# STM32MP23_CM33 register map
File version: 1.2
CPU: CM33 r0p1, little endian, MPU, FPU, vendor SysTick, 8 interrupt priority bits
Registers are 32-bit, read-write, reset 0x0 unless marked. A register's access mark holds for its fields unless they carry their own. Offsets are from the block's base; [hi:lo] are bit positions; {n}, {i} and the like mark numbered series; 'fields as' and 'values as' point back to an identical list.

## BSEC — BSEC register block
Base 0x44000000
Same registers: BSEC_S 0x54000000
{0x0+4i} BSEC_FVR{i} reset not defined (i=0..375) — BSEC fuse word {i} value register
  [31:0] FV — fuse value
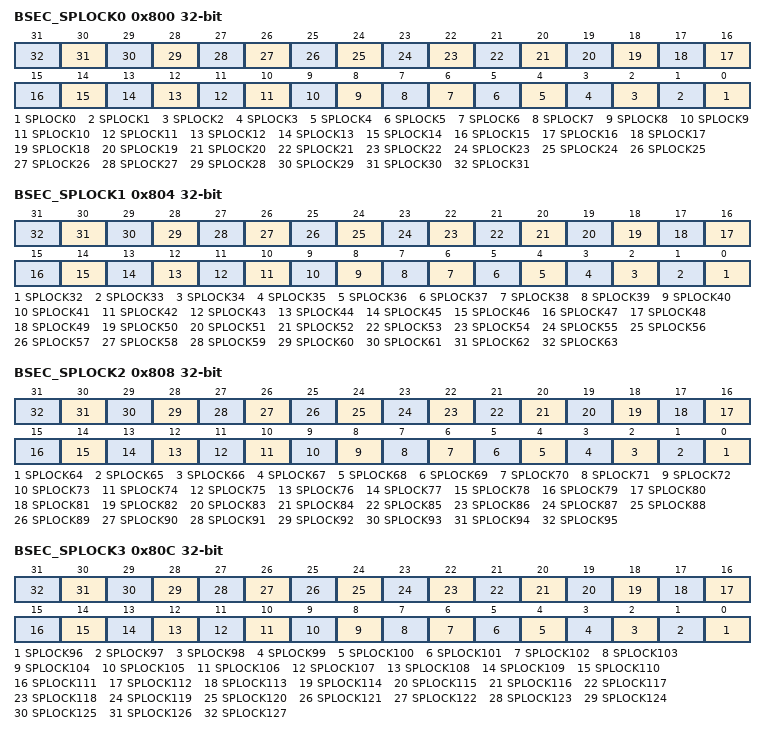
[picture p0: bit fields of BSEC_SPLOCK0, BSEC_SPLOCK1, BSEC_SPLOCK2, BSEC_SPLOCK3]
0x800 BSEC_SPLOCK0 — BSEC sticky programming lock register 0
  [n] SPLOCK{n} (n=0..31) — Sticky programming lock for word {n}
    0=Fuse word {n} can be burnt in fuse memory array; 1=Attempt to program fuse word {n} in OTP memory array is silently ignored
0x804 BSEC_SPLOCK1 — BSEC sticky programming lock register 1
  [n-32] SPLOCK{n} (n=32..63) — Sticky programming lock for word {n}
    values as BSEC_SPLOCK0.SPLOCK0
0x808 BSEC_SPLOCK2 — BSEC sticky programming lock register 2
  [n-64] SPLOCK{n} (n=64..95) — Sticky programming lock for word {n}
    values as BSEC_SPLOCK0.SPLOCK0
0x80C BSEC_SPLOCK3 — BSEC sticky programming lock register 3
  [n-96] SPLOCK{n} (n=96..127) — Sticky programming lock for word {n}
    values as BSEC_SPLOCK0.SPLOCK0
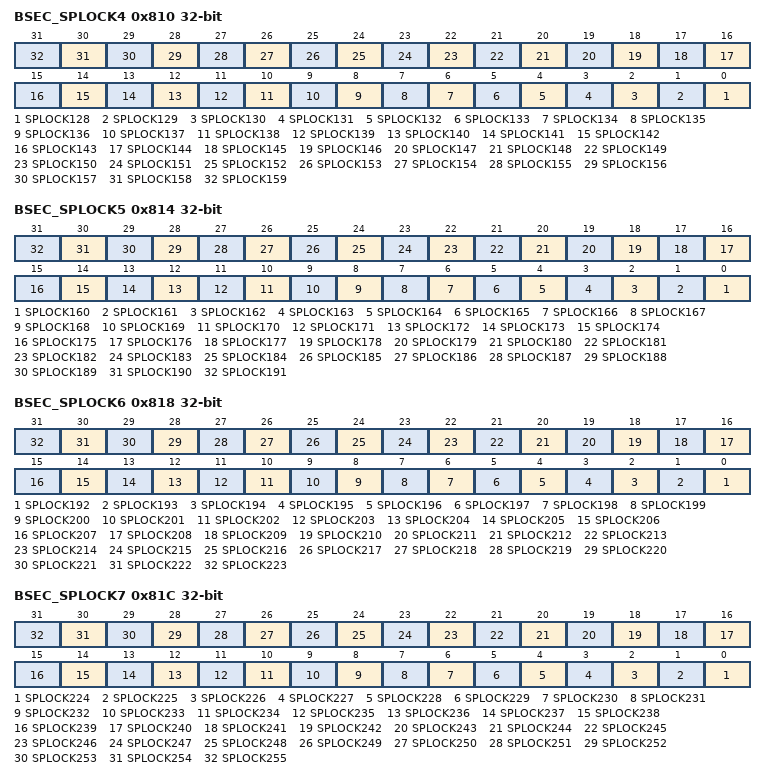
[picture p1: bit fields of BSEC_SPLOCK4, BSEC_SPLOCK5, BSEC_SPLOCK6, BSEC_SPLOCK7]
0x810 BSEC_SPLOCK4 — BSEC sticky programming lock register 4
  [n-128] SPLOCK{n} (n=128..159) — Sticky programming lock for word {n}
    values as BSEC_SPLOCK0.SPLOCK0
0x814 BSEC_SPLOCK5 — BSEC sticky programming lock register 5
  [n-160] SPLOCK{n} (n=160..191) — Sticky programming lock for word {n}
    values as BSEC_SPLOCK0.SPLOCK0
0x818 BSEC_SPLOCK6 — BSEC sticky programming lock register 6
  [n-192] SPLOCK{n} (n=192..223) — Sticky programming lock for word {n}
    values as BSEC_SPLOCK0.SPLOCK0
0x81C BSEC_SPLOCK7 — BSEC sticky programming lock register 7
  [n-224] SPLOCK{n} (n=224..255) — Sticky programming lock for word {n}
    values as BSEC_SPLOCK0.SPLOCK0
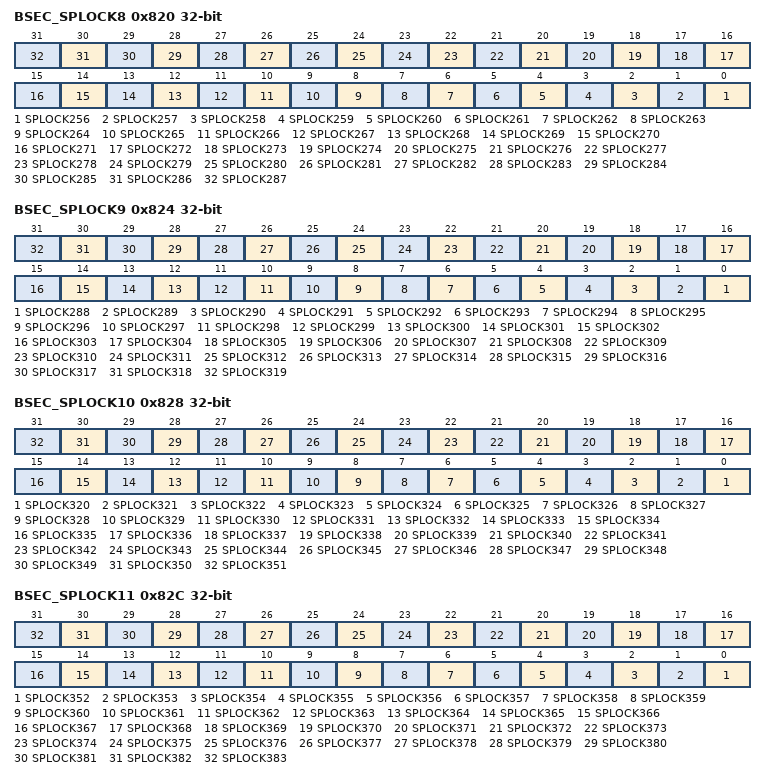
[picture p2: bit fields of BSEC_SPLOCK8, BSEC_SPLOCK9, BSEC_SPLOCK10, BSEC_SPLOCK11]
0x820 BSEC_SPLOCK8 — BSEC sticky programming lock register 8
  [n-256] SPLOCK{n} (n=256..287) — Sticky programming lock for word {n}
    values as BSEC_SPLOCK0.SPLOCK0
0x824 BSEC_SPLOCK9 — BSEC sticky programming lock register 9
  [n-288] SPLOCK{n} (n=288..319) — Sticky programming lock for word {n}
    values as BSEC_SPLOCK0.SPLOCK0
0x828 BSEC_SPLOCK10 — BSEC sticky programming lock register 10
  [n-320] SPLOCK{n} (n=320..351) — Sticky programming lock for word {n}
    values as BSEC_SPLOCK0.SPLOCK0
0x82C BSEC_SPLOCK11 — BSEC sticky programming lock register 11
  [n-352] SPLOCK{n} (n=352..383) — Sticky programming lock for word {n}
    values as BSEC_SPLOCK0.SPLOCK0
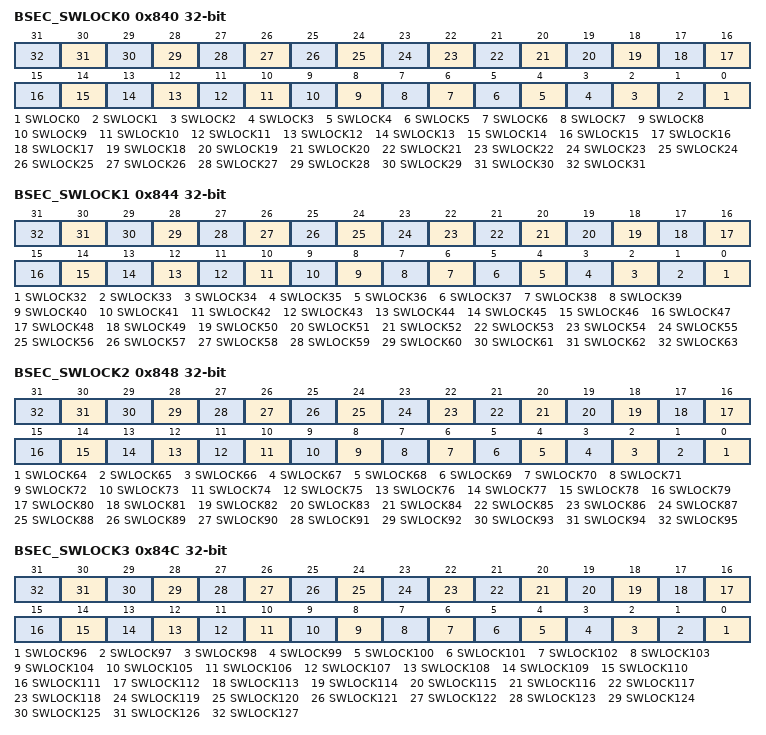
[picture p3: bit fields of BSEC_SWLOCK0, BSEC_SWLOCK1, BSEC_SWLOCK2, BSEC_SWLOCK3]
0x840 BSEC_SWLOCK0 — BSEC sticky write lock register 0
  [n] SWLOCK{n} (n=0..31) — sticky write lock for shadow register {n}
    0=Write to shadow register BSEC_FVR{n} is allowed; 1=Writes to shadow register BSEC_FVR{n} are silently ignored
0x844 BSEC_SWLOCK1 — BSEC sticky write lock register 1
  [n-32] SWLOCK{n} (n=32..63) — sticky write lock for shadow register {n}
    values as BSEC_SWLOCK0.SWLOCK0
0x848 BSEC_SWLOCK2 — BSEC sticky write lock register 2
  [n-64] SWLOCK{n} (n=64..95) — sticky write lock for shadow register {n}
    values as BSEC_SWLOCK0.SWLOCK0
0x84C BSEC_SWLOCK3 — BSEC sticky write lock register 3
  [n-96] SWLOCK{n} (n=96..127) — sticky write lock for shadow register {n}
    values as BSEC_SWLOCK0.SWLOCK0
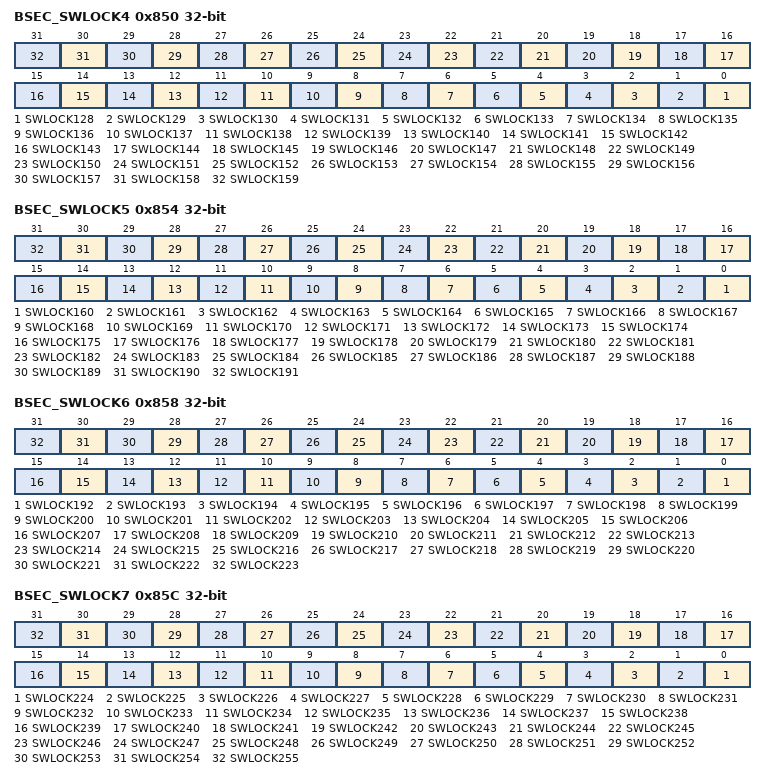
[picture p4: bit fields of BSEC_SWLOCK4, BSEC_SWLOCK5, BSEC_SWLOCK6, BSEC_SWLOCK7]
0x850 BSEC_SWLOCK4 — BSEC sticky write lock register 4
  [n-128] SWLOCK{n} (n=128..159) — sticky write lock for shadow register {n}
    values as BSEC_SWLOCK0.SWLOCK0
0x854 BSEC_SWLOCK5 — BSEC sticky write lock register 5
  [n-160] SWLOCK{n} (n=160..191) — sticky write lock for shadow register {n}
    values as BSEC_SWLOCK0.SWLOCK0
0x858 BSEC_SWLOCK6 — BSEC sticky write lock register 6
  [n-192] SWLOCK{n} (n=192..223) — sticky write lock for shadow register {n}
    values as BSEC_SWLOCK0.SWLOCK0
0x85C BSEC_SWLOCK7 — BSEC sticky write lock register 7
  [n-224] SWLOCK{n} (n=224..255) — sticky write lock for shadow register {n}
    values as BSEC_SWLOCK0.SWLOCK0
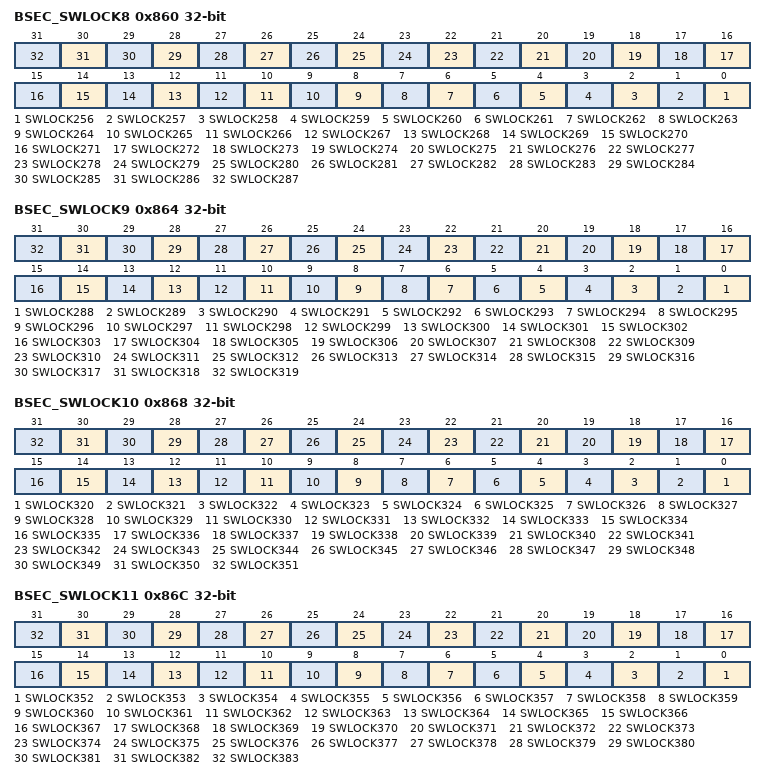
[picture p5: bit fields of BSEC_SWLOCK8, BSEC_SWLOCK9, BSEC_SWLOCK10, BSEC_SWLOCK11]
0x860 BSEC_SWLOCK8 — BSEC sticky write lock register 8
  [n-256] SWLOCK{n} (n=256..287) — sticky write lock for shadow register {n}
    values as BSEC_SWLOCK0.SWLOCK0
0x864 BSEC_SWLOCK9 — BSEC sticky write lock register 9
  [n-288] SWLOCK{n} (n=288..319) — sticky write lock for shadow register {n}
    values as BSEC_SWLOCK0.SWLOCK0
0x868 BSEC_SWLOCK10 — BSEC sticky write lock register 10
  [n-320] SWLOCK{n} (n=320..351) — sticky write lock for shadow register {n}
    values as BSEC_SWLOCK0.SWLOCK0
0x86C BSEC_SWLOCK11 — BSEC sticky write lock register 11
  [n-352] SWLOCK{n} (n=352..383) — sticky write lock for shadow register {n}
    values as BSEC_SWLOCK0.SWLOCK0
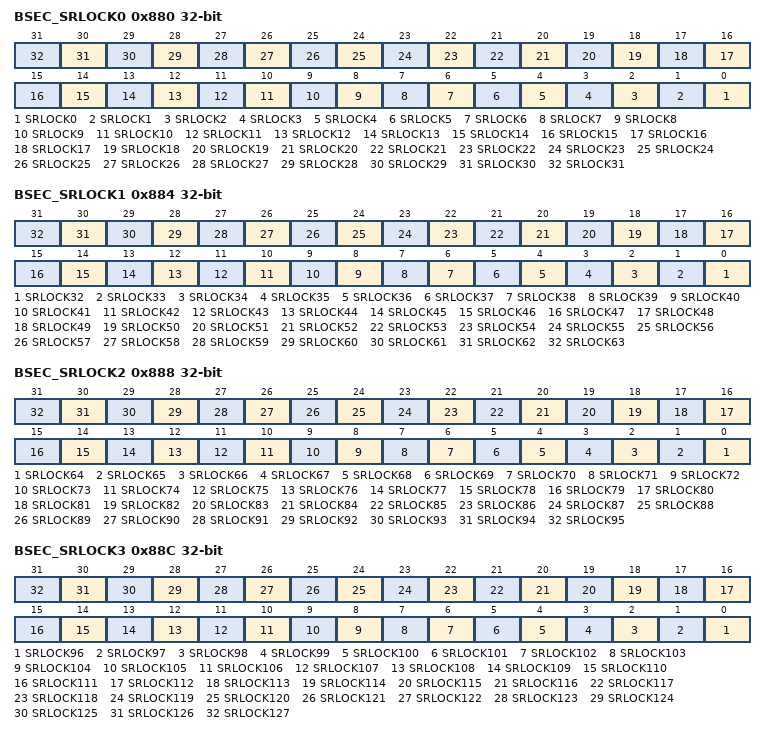
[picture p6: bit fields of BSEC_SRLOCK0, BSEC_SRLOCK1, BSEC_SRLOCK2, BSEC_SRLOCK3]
0x880 BSEC_SRLOCK0 — BSEC sticky reload lock register 0
  [n] SRLOCK{n} (n=0..31) — sticky reload lock for fuse word {n}
    0=Fuse word {n} loading through BSEC_OTPCR is authorized; 1=Fuse word {n} loading through BSEC_OTPCR is denied until next cold or warm reset
0x884 BSEC_SRLOCK1 — BSEC sticky reload lock register 1
  [n-32] SRLOCK{n} (n=32..63) — sticky reload lock for fuse word {n}
    values as BSEC_SRLOCK0.SRLOCK0
0x888 BSEC_SRLOCK2 — BSEC sticky reload lock register 2
  [n-64] SRLOCK{n} (n=64..95) — sticky reload lock for fuse word {n}
    values as BSEC_SRLOCK0.SRLOCK0
0x88C BSEC_SRLOCK3 — BSEC sticky reload lock register 3
  [n-96] SRLOCK{n} (n=96..127) — sticky reload lock for fuse word {n}
    values as BSEC_SRLOCK0.SRLOCK0
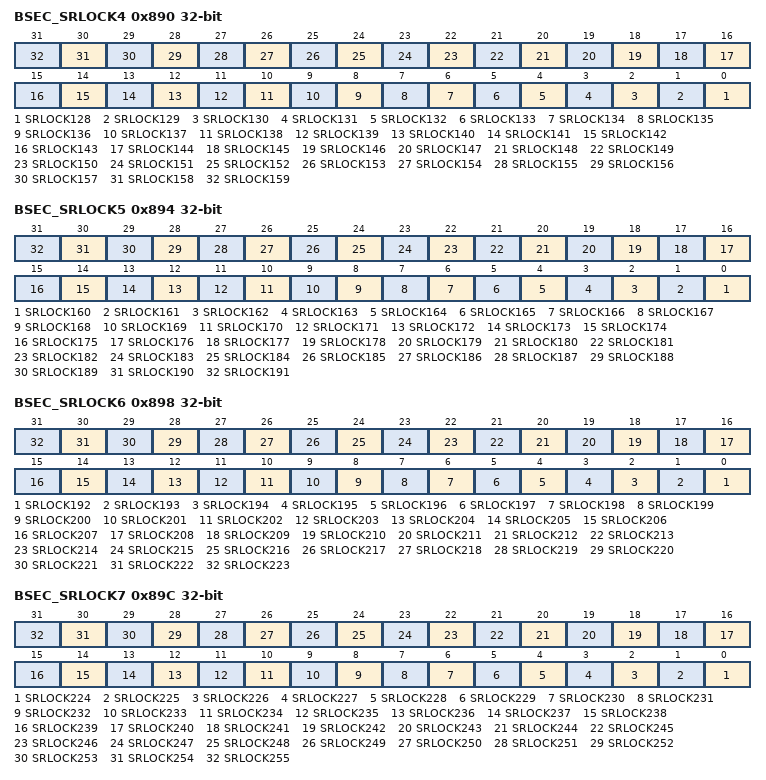
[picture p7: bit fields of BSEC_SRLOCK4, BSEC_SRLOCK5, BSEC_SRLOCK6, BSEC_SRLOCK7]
0x890 BSEC_SRLOCK4 — BSEC sticky reload lock register 4
  [n-128] SRLOCK{n} (n=128..159) — sticky reload lock for fuse word {n}
    values as BSEC_SRLOCK0.SRLOCK0
0x894 BSEC_SRLOCK5 — BSEC sticky reload lock register 5
  [n-160] SRLOCK{n} (n=160..191) — sticky reload lock for fuse word {n}
    values as BSEC_SRLOCK0.SRLOCK0
0x898 BSEC_SRLOCK6 — BSEC sticky reload lock register 6
  [n-192] SRLOCK{n} (n=192..223) — sticky reload lock for fuse word {n}
    values as BSEC_SRLOCK0.SRLOCK0
0x89C BSEC_SRLOCK7 — BSEC sticky reload lock register 7
  [n-224] SRLOCK{n} (n=224..255) — sticky reload lock for fuse word {n}
    values as BSEC_SRLOCK0.SRLOCK0
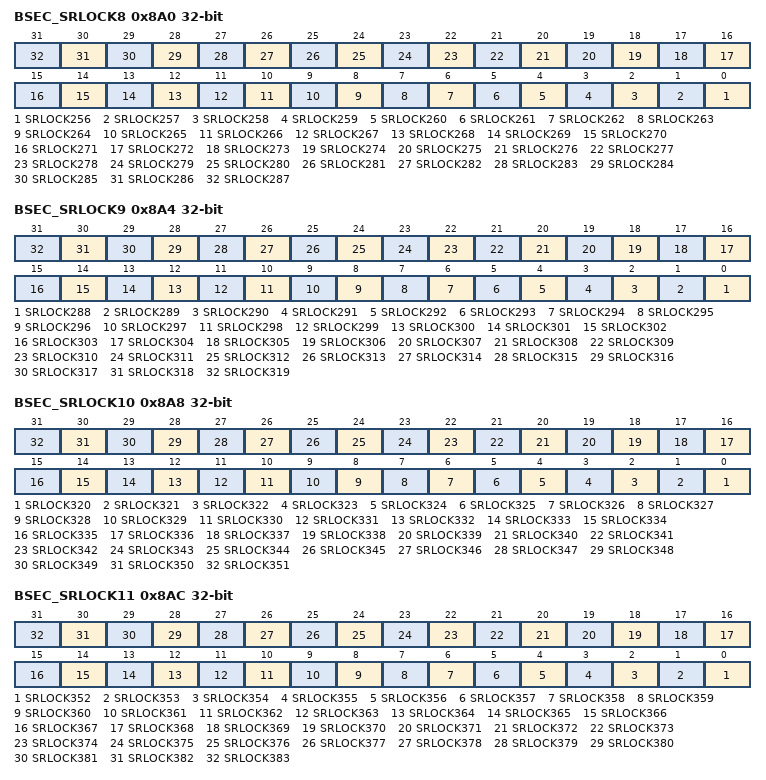
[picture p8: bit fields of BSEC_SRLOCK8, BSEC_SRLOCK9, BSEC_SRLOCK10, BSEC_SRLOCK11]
0x8A0 BSEC_SRLOCK8 — BSEC sticky reload lock register 8
  [n-256] SRLOCK{n} (n=256..287) — sticky reload lock for fuse word {n}
    values as BSEC_SRLOCK0.SRLOCK0
0x8A4 BSEC_SRLOCK9 — BSEC sticky reload lock register 9
  [n-288] SRLOCK{n} (n=288..319) — sticky reload lock for fuse word {n}
    values as BSEC_SRLOCK0.SRLOCK0
0x8A8 BSEC_SRLOCK10 — BSEC sticky reload lock register 10
  [n-320] SRLOCK{n} (n=320..351) — sticky reload lock for fuse word {n}
    values as BSEC_SRLOCK0.SRLOCK0
0x8AC BSEC_SRLOCK11 — BSEC sticky reload lock register 11
  [n-352] SRLOCK{n} (n=352..383) — sticky reload lock for fuse word {n}
    values as BSEC_SRLOCK0.SRLOCK0
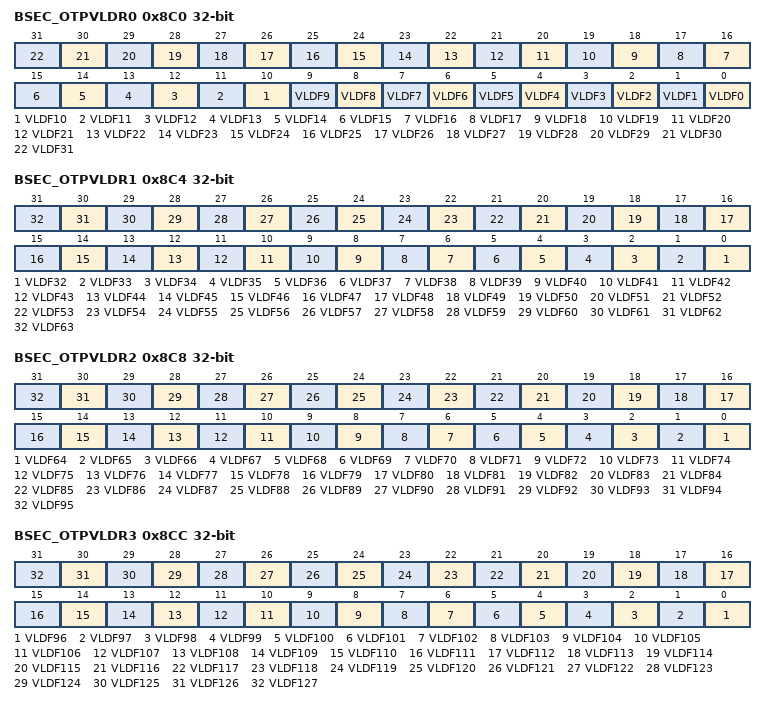
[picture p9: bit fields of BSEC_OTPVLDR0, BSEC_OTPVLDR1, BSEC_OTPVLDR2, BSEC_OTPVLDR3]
0x8C0 BSEC_OTPVLDR0 ro — BSEC OTP valid register 0
  [n] VLDF{n} (n=0..31) — Valid flag for shadow register {n}
    0=An error occurred while fuse word {n} was last reloaded; 1=Last reload of fuse word {n} was done without error
0x8C4 BSEC_OTPVLDR1 ro — BSEC OTP valid register 1
  [n-32] VLDF{n} (n=32..63) — Valid flag for shadow register {n}
    values as BSEC_OTPVLDR0.VLDF0
0x8C8 BSEC_OTPVLDR2 ro — BSEC OTP valid register 2
  [n-64] VLDF{n} (n=64..95) — Valid flag for shadow register {n}
    values as BSEC_OTPVLDR0.VLDF0
0x8CC BSEC_OTPVLDR3 ro — BSEC OTP valid register 3
  [n-96] VLDF{n} (n=96..127) — Valid flag for shadow register {n}
    values as BSEC_OTPVLDR0.VLDF0
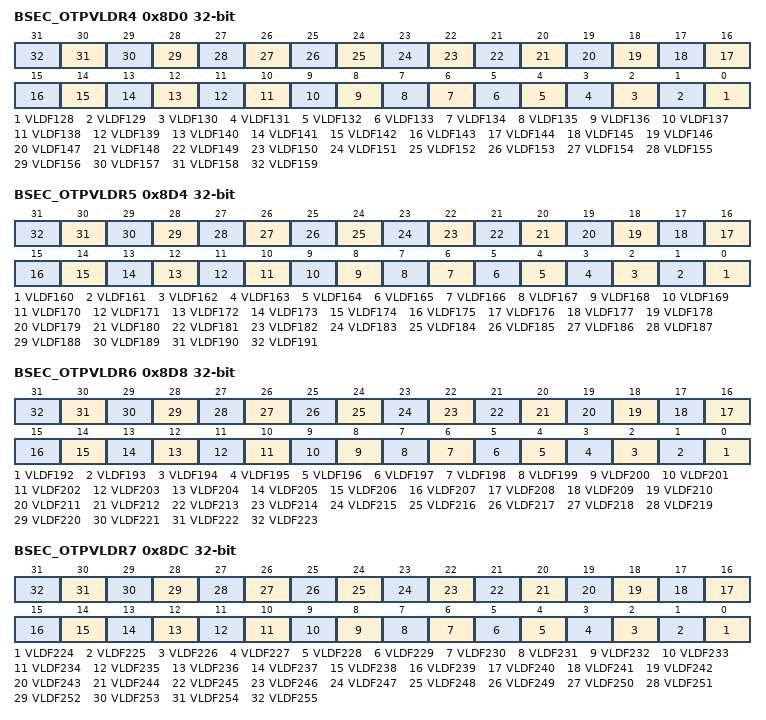
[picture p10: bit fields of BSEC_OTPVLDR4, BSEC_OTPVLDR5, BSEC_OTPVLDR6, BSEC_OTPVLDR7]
0x8D0 BSEC_OTPVLDR4 ro — BSEC OTP valid register 4
  [n-128] VLDF{n} (n=128..159) — Valid flag for shadow register {n}
    values as BSEC_OTPVLDR0.VLDF0
0x8D4 BSEC_OTPVLDR5 ro — BSEC OTP valid register 5
  [n-160] VLDF{n} (n=160..191) — Valid flag for shadow register {n}
    values as BSEC_OTPVLDR0.VLDF0
0x8D8 BSEC_OTPVLDR6 ro — BSEC OTP valid register 6
  [n-192] VLDF{n} (n=192..223) — Valid flag for shadow register {n}
    values as BSEC_OTPVLDR0.VLDF0
0x8DC BSEC_OTPVLDR7 ro — BSEC OTP valid register 7
  [n-224] VLDF{n} (n=224..255) — Valid flag for shadow register {n}
    values as BSEC_OTPVLDR0.VLDF0
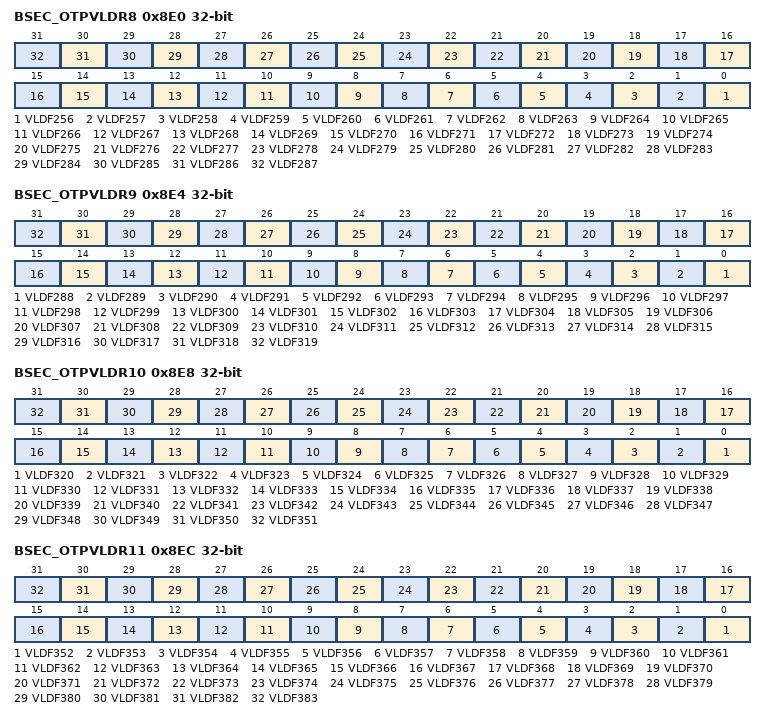
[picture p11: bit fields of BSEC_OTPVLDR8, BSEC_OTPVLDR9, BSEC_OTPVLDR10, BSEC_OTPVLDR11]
0x8E0 BSEC_OTPVLDR8 ro — BSEC OTP valid register 8
  [n-256] VLDF{n} (n=256..287) — Valid flag for shadow register {n}
    values as BSEC_OTPVLDR0.VLDF0
0x8E4 BSEC_OTPVLDR9 ro — BSEC OTP valid register 9
  [n-288] VLDF{n} (n=288..319) — Valid flag for shadow register {n}
    values as BSEC_OTPVLDR0.VLDF0
0x8E8 BSEC_OTPVLDR10 ro — BSEC OTP valid register 10
  [n-320] VLDF{n} (n=320..351) — Valid flag for shadow register {n}
    values as BSEC_OTPVLDR0.VLDF0
0x8EC BSEC_OTPVLDR11 ro — BSEC OTP valid register 11
  [n-352] VLDF{n} (n=352..383) — Valid flag for shadow register {n}
    values as BSEC_OTPVLDR0.VLDF0
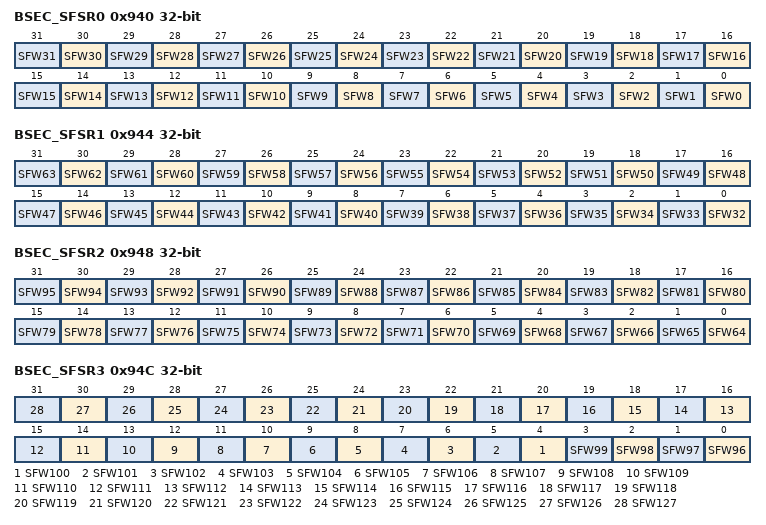
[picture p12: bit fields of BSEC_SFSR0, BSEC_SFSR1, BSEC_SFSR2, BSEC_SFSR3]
0x940 BSEC_SFSR0 ro — BSEC shadowed fuses status register 0
  [n] SFW{n} (n=0..31) — Shadowed fuse word {n}
    0=Fuse word {n} is not shadowed; 1=Fuse word is shadowed in BSEC_FVR{n} register
0x944 BSEC_SFSR1 ro — BSEC shadowed fuses status register 1
  [n-32] SFW{n} (n=32..63) — Shadowed fuse word {n}
    values as BSEC_SFSR0.SFW0
0x948 BSEC_SFSR2 ro — BSEC shadowed fuses status register 2
  [n-64] SFW{n} (n=64..95) — Shadowed fuse word {n}
    values as BSEC_SFSR0.SFW0
0x94C BSEC_SFSR3 ro — BSEC shadowed fuses status register 3
  [n-96] SFW{n} (n=96..127) — Shadowed fuse word {n}
    values as BSEC_SFSR0.SFW0
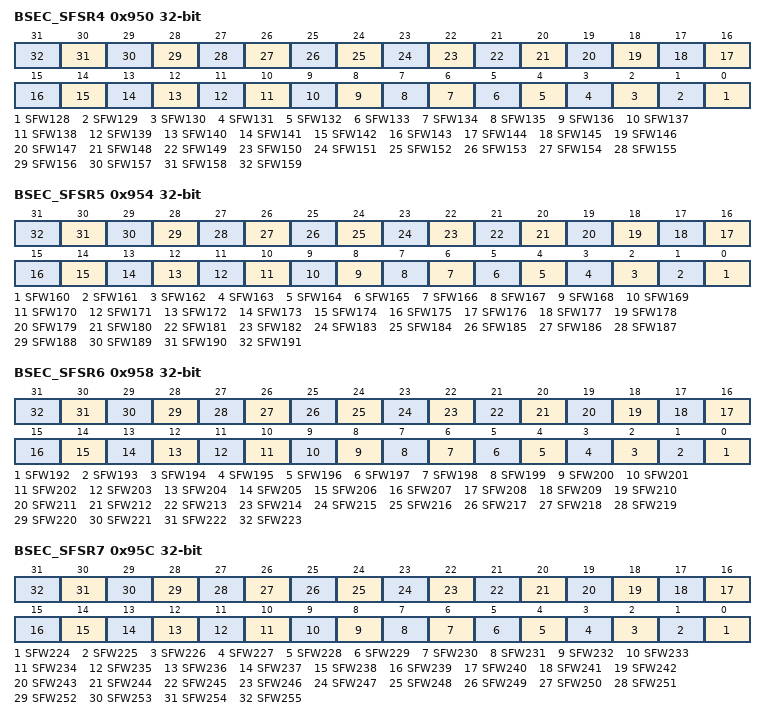
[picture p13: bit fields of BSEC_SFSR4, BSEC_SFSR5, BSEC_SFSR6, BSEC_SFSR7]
0x950 BSEC_SFSR4 ro — BSEC shadowed fuses status register 4
  [n-128] SFW{n} (n=128..159) — Shadowed fuse word {n}
    values as BSEC_SFSR0.SFW0
0x954 BSEC_SFSR5 ro — BSEC shadowed fuses status register 5
  [n-160] SFW{n} (n=160..191) — Shadowed fuse word {n}
    values as BSEC_SFSR0.SFW0
0x958 BSEC_SFSR6 ro — BSEC shadowed fuses status register 6
  [n-192] SFW{n} (n=192..223) — Shadowed fuse word {n}
    values as BSEC_SFSR0.SFW0
0x95C BSEC_SFSR7 ro — BSEC shadowed fuses status register 7
  [n-224] SFW{n} (n=224..255) — Shadowed fuse word {n}
    values as BSEC_SFSR0.SFW0
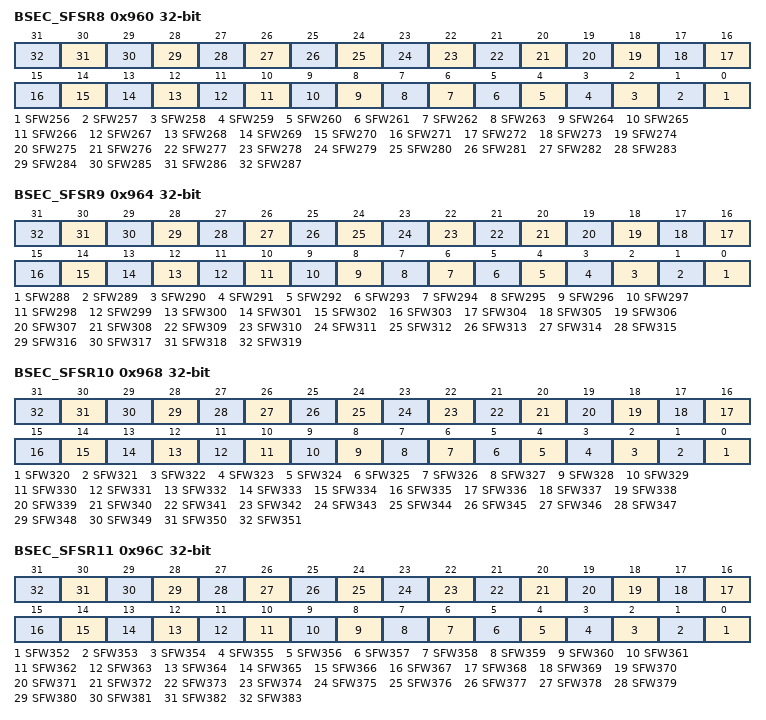
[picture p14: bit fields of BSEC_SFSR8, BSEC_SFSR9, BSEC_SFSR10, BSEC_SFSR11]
0x960 BSEC_SFSR8 ro — BSEC shadowed fuses status register 8
  [n-256] SFW{n} (n=256..287) — Shadowed fuse word {n}
    values as BSEC_SFSR0.SFW0
0x964 BSEC_SFSR9 ro — BSEC shadowed fuses status register 9
  [n-288] SFW{n} (n=288..319) — Shadowed fuse word {n}
    values as BSEC_SFSR0.SFW0
0x968 BSEC_SFSR10 ro — BSEC shadowed fuses status register 10
  [n-320] SFW{n} (n=320..351) — Shadowed fuse word {n}
    values as BSEC_SFSR0.SFW0
0x96C BSEC_SFSR11 ro — BSEC shadowed fuses status register 11
  [n-352] SFW{n} (n=352..383) — Shadowed fuse word {n}
    values as BSEC_SFSR0.SFW0
0xC04 BSEC_OTPCR — BSEC OTP control register
  [21:19] LASTCID ro
  [14] PPLOCK — Permanent programming lock
    0=Fuse word at address ADDR[8:0] is programmed normally; 1=Fuse word at address ADDR[8:0] is locked, preventing further modifications
  [13] PROG — Fuse word programming
    0=Fuse word read operation is required; 1=Fuse word programming operation is required
  [8:0] ADDR — Fuse word address
0xC08 BSEC_WDR wo — BSEC write data register
  [31:0] WRDATA — OTP write data
{0xE00+4i} BSEC_SCRATCHR{i} (i=0..3) — BSEC scratch register {i}
  [31:0] SDATA — Scratch data
0xE10 BSEC_LOCKR — BSEC lock register
  [2] HKLOCK — Hardware key lock
    0=Derived hardware unique key (DHUK) in SAES peripheral is usable if HVALID is set in BSEC_SR; 1=Derived hardware unique key (DHUK) in SAES peripheral is not usable
  [1] DENLOCK — Debug enable register sticky lock
    0=Writes to BSEC_DENR register are allowed; 1=Writes to BSEC_DENR register are ignored
  [0] GWLOCK — Global write lock
    0=Writes to BSEC registers are allowed; 1=Writes to BSEC registers are ignored (fuse programming and fuse reload disabled)
0xE14 BSEC_JTAGINR ro — BSEC JTAG input register
  [31:0] JDATAIN — JTAG input data
0xE18 BSEC_JTAGOUTR wo — BSEC JTAG output register
  [31:0] JDATAOUT — JTAG output data
0xE20 BSEC_DENR — BSEC debug enable register
  [14:13] CP15SDIS — CP15SDISABLE for core x (x = 0 or 1)
    0=All CP15 registers of Cortex-A core x can be written in secure mode; 1=Write access to some of the CP15 secure registers of Cortex-A core x are ignored
  [12] CFGSDIS — CFGSDISABLE
    0=All GIC-400 registers can be written in secure mode; 1=Write access to some of GIC-400 secure registers are ignored
  [11] SPNIDENM — Secure privilege non-invasive debug enable for Cortex-M
    0=Secure privilege non-invasive debug is disabled for Cortex-M; 1=Secure privilege non-invasive debug is enabled for Cortex-M
  [10] SPIDENM — Secure privilege invasive debug enable for Cortex-M
    0=Secure privilege invasive debug is disabled for Cortex-M; 1=Secure privilege invasive debug is enabled for Cortex-M
  [9] NIDENM — Non invasive debug enable for Cortex-M
    0=Non invasive debug is disabled for Cortex-M; 1=Non invasive debug is enabled for Cortex-M
  [8] DBGENM — Debug enable for Cortex-M
    0=Disabled; 1=Enabled
  [7] DBGSWEN — Self-hosted debug enable
    0=Software access to all debug components is disabled; 1=Software access to all debug components is enabled
  [6] SPNIDENA — Secure privilege non-invasive debug enable for Cortex-A
    0=Secure privilege non-invasive debug is disabled for Cortex-A; 1=Secure privilege non-invasive debug is enabled for Cortex-A
  [5] SPIDENA — Secure privilege invasive debug enable for Cortex-A
    0=Secure privilege invasive debug is disabled for Cortex-A; 1=Secure privilege invasive debug is enabled for Cortex-A
  [4] HDPEN — Hardware debug port enable
    0=Hardware debug tracing port is disabled; 1=Hardware debug tracing port is enabled
  [3] DEVICEEN — Device debug enable
    0=External debugger is not usable with the device; 1=External debugger is usable with the device, depending on the value stored in this register
  [2] NIDENA — Non invasive debug enable for Cortex-A
    0=Non invasive debug is disabled for Cortex-A; 1=Non invasive debug is enabled for Cortex-A
  [1] DBGENA — Debug enable for Cortex-A
    0=Disabled; 1=Enabled
0xE24 BSEC_UNMAPR reset not defined — BSEC unmap register
  [31:0] UNMAP — Unmap key
0xE40 BSEC_SR ro — BSEC status register
  [31:26] NVSTATE — Non-volatile state
    22=BSEC-open state; 13=BSEC-closed state; 7=BSEC-invalid state; 35=BSEC-invalid state, with an active confirmed tamper triggered in the device
  [1] HVALID — Hardware key valid
    0=Derived hardware unique key (DHUK) feature cannot be used in SAES peripheral; 1=Derived hardware unique key (DHUK) feature can be used in SAES peripheral
0xE44 BSEC_OTPSR ro — BSEC OTP status register
  [22] AMEF — Addresses mismatch error flag
  [21] PPLMF — Permanent programming lock mismatch flag
  [20] PPLF — Permanent programming lock flag
  [19] SECF — Single error correction flag
  [18] DEDF — Double error detection flag
  [17] DISTURBF — Disturb flag
  [16] PROGFAIL — Programming failed
  [6] OTPSEC — OTP with single error correction
  [5] OTPERR — OTP with error
  [4] OTPNVIR — OTP not virgin
  [2] HIDEUP — Hide upper fuse words
  [1] INIT_DONE — Initialization done
  [0] BUSY — Busy flag
    0=BSEC is idle; 1=BSEC is busy
{0xF40+4i} BSEC_WOSCR{i} rw-once (i=0..7) — BSEC write once scratch register {i}
  [31:0] WOSDATA — Write once scratch data
0xFE8 BSEC_HRCR ro — BSEC hot reset count register
  [31:0] HRC — Hot reset counter
0xFEC BSEC_WRCR ro — BSEC warm reset count register
  [31:0] WRC — Warm reset counter
0xFF4 BSEC_VERR ro reset 0x10 — BSEC version register
  [7:4] MAJREV — Major revision
  [3:0] MINREV — Minor revision
0xFF8 BSEC_IPIDR ro reset 0x100033 — BSEC identification register
  [31:0] ID — BSEC identification
0xFFC BSEC_SIDR ro reset 0xA3C5DD04 — BSEC size identification register
  [31:0] SID — BSEC size identification
